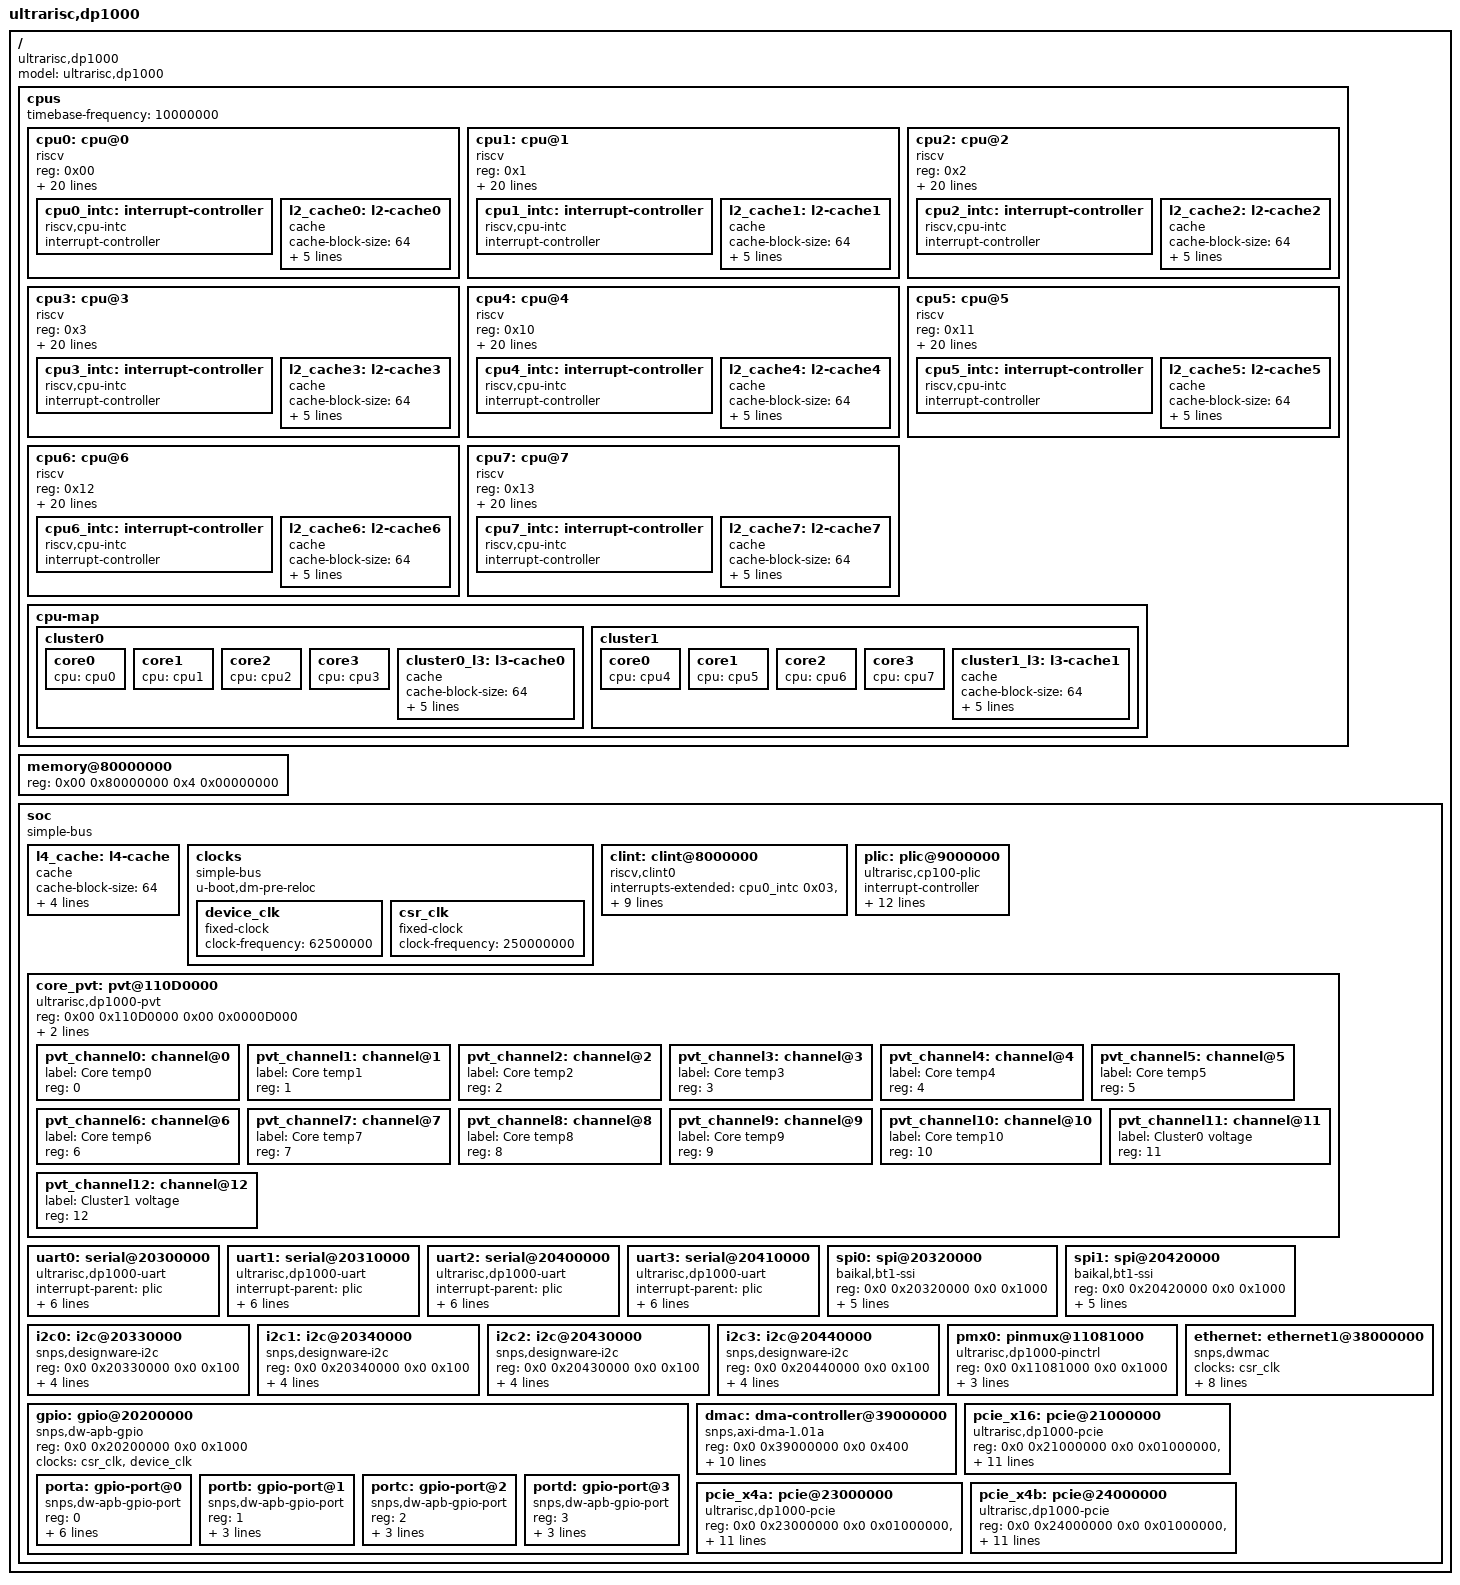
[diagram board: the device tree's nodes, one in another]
// SPDX-License-Identifier: GPL-2.0
/*
 * Copyright(C) 2025 UltraRISC Technology (Shanghai) Co., Ltd.
 */

/dts-v1/;

/ {
	#address-cells = <0x02>;
	#size-cells = <0x02>;
	compatible = "ultrarisc,dp1000";
	model = "ultrarisc,dp1000";

	cpus {
		#address-cells = <0x01>;
		#size-cells = <0x00>;
		timebase-frequency = <10000000>;

		cpu0: cpu@0 {
			device_type = "cpu";
			reg = <0x00>;
			status = "okay";
			compatible = "riscv";
			riscv,isa = "rv64imafdcbh";
			riscv,isa-base = "rv64i";
			riscv,isa-extensions = "i","m","a","f","d","c","h","zba",
					       "zbb","zbc","zbs","zicntr","zicsr",
					       "zifencei","zihpm","ziccif","ziccrse",
					       "ziccamoa","za64rs","zic64b","zicbom",
					       "zicbop","zicboz","zkt","zama16b",
					       "svade","ssccptr","sstvecd","sscounterenw",
					       "shcounterenw","shtvala","shvstvecd",
					       "shvsatpa","ssstrict","svvptc";
			mmu-type = "riscv,sv48";
			clock-frequency = <2000000000>;
			/* L1 I-cache and D-cache:
			 * block-size 64B
			 * 4-way set associative, size 64KB
			 * per-core.
			 */
			d-cache-block-size = <64>;
			d-cache-sets = <256>;
			d-cache-size = <0x10000>;
			i-cache-block-size = <64>;
			i-cache-sets = <256>;
			i-cache-size = <0x10000>;
			next-level-cache = <&l2_cache0>;
			riscv,cbom-block-size = <64>;
			riscv,cboz-block-size = <64>;
			cpu0_intc:interrupt-controller {
				#address-cells = <0x01>;
				interrupt-controller;
				compatible = "riscv,cpu-intc";
				#interrupt-cells = <0x01>;
			};
			l2_cache0: l2-cache0 {
				/* L2 cache:
				 * cache-unified, block-size 64B
				 * 8-way set associative, size 512KB
				 * per-core.
				 */
				compatible = "cache";
				cache-block-size = <64>;
				cache-level = <2>;
				cache-size = <0x80000>;
				cache-sets = <1024>;
				cache-unified;
				next-level-cache = <&cluster0_l3>;
			};
		};
		cpu1: cpu@1 {
			device_type = "cpu";
			reg = <0x1>;
			status = "okay";
			compatible = "riscv";
			riscv,isa = "rv64imafdcbh";
			riscv,isa-base = "rv64i";
			riscv,isa-extensions = "i","m","a","f","d","c","h","zba",
					       "zbb","zbc","zbs","zicntr","zicsr",
					       "zifencei","zihpm","ziccif","ziccrse",
					       "ziccamoa","za64rs","zic64b","zicbom",
					       "zicbop","zicboz","zkt","zama16b",
					       "svade","ssccptr","sstvecd","sscounterenw",
					       "shcounterenw","shtvala","shvstvecd",
					       "shvsatpa","ssstrict","svvptc";
			mmu-type = "riscv,sv48";
			clock-frequency = <2000000000>;
			/* L1 I-cache and D-cache:
			 * block-size 64B
			 * 4-way set associative, size 64KB
			 * per-core.
			 */
			d-cache-block-size = <64>;
			d-cache-sets = <256>;
			d-cache-size = <0x10000>;
			i-cache-block-size = <64>;
			i-cache-sets = <256>;
			i-cache-size = <0x10000>;
			next-level-cache = <&l2_cache1>;
			riscv,cbom-block-size = <64>;
			riscv,cboz-block-size = <64>;
			cpu1_intc:interrupt-controller {
				#address-cells = <0x01>;
				interrupt-controller;
				compatible = "riscv,cpu-intc";
				#interrupt-cells = <0x01>;
			};
			l2_cache1: l2-cache1 {
				/* L2 cache:
				 * cache-unified, block-size 64B
				 * 8-way set associative, size 512KB
				 * per-core.
				 */
				compatible = "cache";
				cache-block-size = <64>;
				cache-level = <2>;
				cache-size = <0x80000>;
				cache-sets = <1024>;
				cache-unified;
				next-level-cache = <&cluster0_l3>;
			};
		};
		cpu2: cpu@2 {
			device_type = "cpu";
			reg = <0x2>;
			status = "okay";
			compatible = "riscv";
			riscv,isa = "rv64imafdcbh";
			riscv,isa-base = "rv64i";
			riscv,isa-extensions = "i","m","a","f","d","c","h","zba",
					       "zbb","zbc","zbs","zicntr","zicsr",
					       "zifencei","zihpm","ziccif","ziccrse",
					       "ziccamoa","za64rs","zic64b","zicbom",
					       "zicbop","zicboz","zkt","zama16b",
					       "svade","ssccptr","sstvecd","sscounterenw",
					       "shcounterenw","shtvala","shvstvecd",
					       "shvsatpa","ssstrict","svvptc";
			mmu-type = "riscv,sv48";
			clock-frequency = <2000000000>;
			/* L1 I-cache and D-cache:
			 * block-size 64B
			 * 4-way set associative, size 64KB
			 * per-core.
			 */
			d-cache-block-size = <64>;
			d-cache-sets = <256>;
			d-cache-size = <0x10000>;
			i-cache-block-size = <64>;
			i-cache-sets = <256>;
			i-cache-size = <0x10000>;
			next-level-cache = <&l2_cache2>;
			riscv,cbom-block-size = <64>;
			riscv,cboz-block-size = <64>;
			cpu2_intc:interrupt-controller {
				#address-cells = <0x01>;
				interrupt-controller;
				compatible = "riscv,cpu-intc";
				#interrupt-cells = <0x01>;
			};
			l2_cache2: l2-cache2 {
				/* L2 cache:
				 * cache-unified, block-size 64B
				 * 8-way set associative, size 512KB
				 * per-core.
				 */
				compatible = "cache";
				cache-block-size = <64>;
				cache-level = <2>;
				cache-size = <0x80000>;
				cache-sets = <1024>;
				cache-unified;
				next-level-cache = <&cluster0_l3>;
			};
		};
		cpu3: cpu@3 {
			device_type = "cpu";
			reg = <0x3>;
			status = "okay";
			compatible = "riscv";
			riscv,isa = "rv64imafdcbh";
			riscv,isa-base = "rv64i";
			riscv,isa-extensions = "i","m","a","f","d","c","h","zba",
					       "zbb","zbc","zbs","zicntr","zicsr",
					       "zifencei","zihpm","ziccif","ziccrse",
					       "ziccamoa","za64rs","zic64b","zicbom",
					       "zicbop","zicboz","zkt","zama16b",
					       "svade","ssccptr","sstvecd","sscounterenw",
					       "shcounterenw","shtvala","shvstvecd",
					       "shvsatpa","ssstrict","svvptc";
			mmu-type = "riscv,sv48";
			clock-frequency = <2000000000>;
			/* L1 I-cache and D-cache:
			 * block-size 64B
			 * 4-way set associative, size 64KB
			 * per-core.
			 */
			d-cache-block-size = <64>;
			d-cache-sets = <256>;
			d-cache-size = <0x10000>;
			i-cache-block-size = <64>;
			i-cache-sets = <256>;
			i-cache-size = <0x10000>;
			next-level-cache = <&l2_cache3>;
			riscv,cbom-block-size = <64>;
			riscv,cboz-block-size = <64>;
			cpu3_intc:interrupt-controller {
				#address-cells = <0x01>;
				interrupt-controller;
				compatible = "riscv,cpu-intc";
				#interrupt-cells = <0x01>;
			};
			l2_cache3: l2-cache3 {
				/* L2 cache:
				 * cache-unified, block-size 64B
				 * 8-way set associative, size 512KB
				 * per-core.
				 */
				compatible = "cache";
				cache-block-size = <64>;
				cache-level = <2>;
				cache-size = <0x80000>;
				cache-sets = <1024>;
				cache-unified;
				next-level-cache = <&cluster0_l3>;
			};
		};
		cpu4: cpu@4 {
			device_type = "cpu";
			reg = <0x10>;
			status = "okay";
			compatible = "riscv";
			riscv,isa = "rv64imafdcbh";
			riscv,isa-base = "rv64i";
			riscv,isa-extensions = "i","m","a","f","d","c","h","zba",
					       "zbb","zbc","zbs","zicntr","zicsr",
					       "zifencei","zihpm","ziccif","ziccrse",
					       "ziccamoa","za64rs","zic64b","zicbom",
					       "zicbop","zicboz","zkt","zama16b",
					       "svade","ssccptr","sstvecd","sscounterenw",
					       "shcounterenw","shtvala","shvstvecd",
					       "shvsatpa","ssstrict","svvptc";
			mmu-type = "riscv,sv48";
			clock-frequency = <2000000000>;
			/* L1 I-cache and D-cache:
			 * block-size 64B
			 * 4-way set associative, size 64KB
			 * per-core.
			 */
			d-cache-block-size = <64>;
			d-cache-sets = <256>;
			d-cache-size = <0x10000>;
			i-cache-block-size = <64>;
			i-cache-sets = <256>;
			i-cache-size = <0x10000>;
			next-level-cache = <&l2_cache4>;
			riscv,cbom-block-size = <64>;
			riscv,cboz-block-size = <64>;
			cpu4_intc:interrupt-controller {
				#address-cells = <0x01>;
				interrupt-controller;
				compatible = "riscv,cpu-intc";
				#interrupt-cells = <0x01>;
			};
			l2_cache4: l2-cache4 {
				/* L2 cache:
				 * cache-unified, block-size 64B
				 * 8-way set associative, size 512KB
				 * per-core.
				 */
				compatible = "cache";
				cache-block-size = <64>;
				cache-level = <2>;
				cache-size = <0x80000>;
				cache-sets = <1024>;
				cache-unified;
				next-level-cache = <&cluster1_l3>;
			};
		};
		cpu5: cpu@5 {
			device_type = "cpu";
			reg = <0x11>;
			status = "okay";
			compatible = "riscv";
			riscv,isa = "rv64imafdcbh";
			riscv,isa-base = "rv64i";
			riscv,isa-extensions = "i","m","a","f","d","c","h","zba",
					       "zbb","zbc","zbs","zicntr","zicsr",
					       "zifencei","zihpm","ziccif","ziccrse",
					       "ziccamoa","za64rs","zic64b","zicbom",
					       "zicbop","zicboz","zkt","zama16b",
					       "svade","ssccptr","sstvecd","sscounterenw",
					       "shcounterenw","shtvala","shvstvecd",
					       "shvsatpa","ssstrict","svvptc";
			mmu-type = "riscv,sv48";
			clock-frequency = <2000000000>;
			/* L1 I-cache and D-cache:
			 * block-size 64B
			 * 4-way set associative, size 64KB
			 * per-core.
			 */
			d-cache-block-size = <64>;
			d-cache-sets = <256>;
			d-cache-size = <0x10000>;
			i-cache-block-size = <64>;
			i-cache-sets = <256>;
			i-cache-size = <0x10000>;
			next-level-cache = <&l2_cache5>;
			riscv,cbom-block-size = <64>;
			riscv,cboz-block-size = <64>;
			cpu5_intc:interrupt-controller {
				#address-cells = <0x01>;
				interrupt-controller;
				compatible = "riscv,cpu-intc";
				#interrupt-cells = <0x01>;
			};
			l2_cache5: l2-cache5 {
				/* L2 cache:
				 * cache-unified, block-size 64B
				 * 8-way set associative, size 512KB
				 * per-core.
				 */
				compatible = "cache";
				cache-block-size = <64>;
				cache-level = <2>;
				cache-size = <0x80000>;
				cache-sets = <1024>;
				cache-unified;
				next-level-cache = <&cluster1_l3>;
			};
		};
		cpu6: cpu@6 {
			device_type = "cpu";
			reg = <0x12>;
			status = "okay";
			compatible = "riscv";
			riscv,isa = "rv64imafdcbh";
			riscv,isa-base = "rv64i";
			riscv,isa-extensions = "i","m","a","f","d","c","h","zba",
					       "zbb","zbc","zbs","zicntr","zicsr",
					       "zifencei","zihpm","ziccif","ziccrse",
					       "ziccamoa","za64rs","zic64b","zicbom",
					       "zicbop","zicboz","zkt","zama16b",
					       "svade","ssccptr","sstvecd","sscounterenw",
					       "shcounterenw","shtvala","shvstvecd",
					       "shvsatpa","ssstrict","svvptc";
			mmu-type = "riscv,sv48";
			clock-frequency = <2000000000>;
			/* L1 I-cache and D-cache:
			 * block-size 64B
			 * 4-way set associative, size 64KB
			 * per-core.
			 */
			d-cache-block-size = <64>;
			d-cache-sets = <256>;
			d-cache-size = <0x10000>;
			i-cache-block-size = <64>;
			i-cache-sets = <256>;
			i-cache-size = <0x10000>;
			next-level-cache = <&l2_cache6>;
			riscv,cbom-block-size = <64>;
			riscv,cboz-block-size = <64>;
			cpu6_intc:interrupt-controller {
				#address-cells = <0x01>;
				interrupt-controller;
				compatible = "riscv,cpu-intc";
				#interrupt-cells = <0x01>;
			};
			l2_cache6: l2-cache6 {
				/* L2 cache:
				 * cache-unified, block-size 64B
				 * 8-way set associative, size 512KB
				 * per-core.
				 */
				compatible = "cache";
				cache-block-size = <64>;
				cache-level = <2>;
				cache-size = <0x80000>;
				cache-sets = <1024>;
				cache-unified;
				next-level-cache = <&cluster1_l3>;
			};
		};
		cpu7: cpu@7 {
			device_type = "cpu";
			reg = <0x13>;
			status = "okay";
			compatible = "riscv";
			riscv,isa = "rv64imafdcbh";
			riscv,isa-base = "rv64i";
			riscv,isa-extensions = "i","m","a","f","d","c","h","zba",
					       "zbb","zbc","zbs","zicntr","zicsr",
					       "zifencei","zihpm","ziccif","ziccrse",
					       "ziccamoa","za64rs","zic64b","zicbom",
					       "zicbop","zicboz","zkt","zama16b",
					       "svade","ssccptr","sstvecd","sscounterenw",
					       "shcounterenw","shtvala","shvstvecd",
					       "shvsatpa","ssstrict","svvptc";
			mmu-type = "riscv,sv48";
			clock-frequency = <2000000000>;
			/* L1 I-cache and D-cache:
			 * block-size 64B
			 * 4-way set associative, size 64KB
			 * per-core.
			 */
			d-cache-block-size = <64>;
			d-cache-sets = <256>;
			d-cache-size = <0x10000>;
			i-cache-block-size = <64>;
			i-cache-sets = <256>;
			i-cache-size = <0x10000>;
			next-level-cache = <&l2_cache7>;
			riscv,cbom-block-size = <64>;
			riscv,cboz-block-size = <64>;
			cpu7_intc:interrupt-controller {
				#address-cells = <0x01>;
				interrupt-controller;
				compatible = "riscv,cpu-intc";
				#interrupt-cells = <0x01>;
			};
			l2_cache7: l2-cache7 {
				/* L2 cache:
				 * cache-unified, block-size 64B
				 * 8-way set associative, size 512KB
				 * per-core.
				 */
				compatible = "cache";
				cache-block-size = <64>;
				cache-level = <2>;
				cache-size = <0x80000>;
				cache-sets = <1024>;
				cache-unified;
				next-level-cache = <&cluster1_l3>;
			};
		};

		cpu-map {
			cluster0: cluster0 {
				core0 {
					cpu = <&cpu0>;
				};
				core1 {
					cpu = <&cpu1>;
				};
				core2 {
					cpu = <&cpu2>;
				};
				core3 {
					cpu = <&cpu3>;
				};

				cluster0_l3: l3-cache0 {
					/* L3 cache:
					 * cache-unified, block-size 64B
					 * 16-way set associative, size 4MB
					 * per-cluster.
					 */
					compatible = "cache";
					cache-block-size = <64>;
					cache-level = <3>;
					cache-size = <0x400000>;
					cache-sets = <0x1000>;
					cache-unified;
					next-level-cache = <&l4_cache>;
				};
			};
			cluster1: cluster1 {
				core0 {
					cpu = <&cpu4>;
				};
				core1 {
					cpu = <&cpu5>;
				};
				core2 {
					cpu = <&cpu6>;
				};
				core3 {
					cpu = <&cpu7>;
				};
				cluster1_l3: l3-cache1 {
					/* L3 cache:
					 * cache-unified, block-size 64B
					 * 16-way set associative, size 4MB
					 * per-cluster.
					 */
					compatible = "cache";
					cache-block-size = <64>;
					cache-level = <3>;
					cache-size = <0x400000>;
					cache-sets = <0x1000>;
					cache-unified;
					next-level-cache = <&l4_cache>;
				};
			};
		};
	};

	memory@80000000 {
		device_type = "memory";
		reg = <0x00 0x80000000 0x4 0x00000000>;
	};

	soc {
		#address-cells = <0x02>;
		#size-cells = <0x02>;
		compatible = "simple-bus";
		ranges;

		l4_cache: l4-cache {
			/* L4 cache:
			 * cache-unified, block-size 64B
			 * 16-way set associative, size 16MB
			 * shared by the SoC.
			 */
			compatible = "cache";
			cache-block-size = <64>;
			cache-level = <4>;
			cache-size = <0x1000000>;
			cache-sets = <0x4000>;
			cache-unified;
		};

		clocks {
			compatible = "simple-bus";
			u-boot,dm-pre-reloc;
			device_clk: device_clk {
				compatible = "fixed-clock";
				clock-frequency = <62500000>;
				#clock-cells = <0>;
			};

			csr_clk: csr_clk {
				compatible = "fixed-clock";
				clock-frequency = <250000000>;
				#clock-cells = <0>;
			};
		};

		clint: clint@8000000 {
			compatible = "riscv,clint0";
			interrupts-extended = <&cpu0_intc 0x03>, <&cpu0_intc 0x07>,
					      <&cpu1_intc 0x03>, <&cpu1_intc 0x07>,
					      <&cpu2_intc 0x03>, <&cpu2_intc 0x07>,
					      <&cpu3_intc 0x03>, <&cpu3_intc 0x07>,
					      <&cpu4_intc 0x03>, <&cpu4_intc 0x07>,
					      <&cpu5_intc 0x03>, <&cpu5_intc 0x07>,
					      <&cpu6_intc 0x03>, <&cpu6_intc 0x07>,
					      <&cpu7_intc 0x03>, <&cpu7_intc 0x07>;
			reg = <0x00 0x8000000 0x00 0x100000>;
		};

		plic: plic@9000000 {
			#interrupt-cells = <1>;
			#address-cells = <0>;
			compatible = "ultrarisc,cp100-plic", "ultrarisc,dp1000-plic";
			interrupt-controller;
			interrupts-extended = <&cpu0_intc 0xb>, <&cpu0_intc 0x9>, <&cpu0_intc 0xa>,
					      <&cpu1_intc 0xb>, <&cpu1_intc 0x9>, <&cpu1_intc 0xa>,
					      <&cpu2_intc 0xb>, <&cpu2_intc 0x9>, <&cpu2_intc 0xa>,
					      <&cpu3_intc 0xb>, <&cpu3_intc 0x9>, <&cpu3_intc 0xa>,
					      <&cpu4_intc 0xb>, <&cpu4_intc 0x9>, <&cpu4_intc 0xa>,
					      <&cpu5_intc 0xb>, <&cpu5_intc 0x9>, <&cpu5_intc 0xa>,
					      <&cpu6_intc 0xb>, <&cpu6_intc 0x9>, <&cpu6_intc 0xa>,
					      <&cpu7_intc 0xb>, <&cpu7_intc 0x9>, <&cpu7_intc 0xa>;
			reg = <0x00 0x9000000 0x00 0x4000000>;
			riscv,max-priority = <0x07>;
			riscv,ndev = <160>;
		};

		core_pvt: pvt@110D0000 {
			compatible = "ultrarisc,dp1000-pvt";
			#address-cells = <1>;
			#size-cells = <0>;
			reg = <0x00 0x110D0000 0x00 0x0000D000>;
			clock-frequency = <250000000>;
			channels = <13>;
			#thermal-sensor-cells = <1>;

			pvt_channel0: channel@0 {
				label = "Core temp0";
				reg = <0>;
			};

			pvt_channel1: channel@1 {
				label = "Core temp1";
				reg = <1>;
			};

			pvt_channel2: channel@2 {
				label = "Core temp2";
				reg = <2>;
			};

			pvt_channel3: channel@3 {
				label = "Core temp3";
				reg = <3>;
			};

			pvt_channel4: channel@4 {
				label = "Core temp4";
				reg = <4>;
			};

			pvt_channel5: channel@5 {
				label = "Core temp5";
				reg = <5>;
			};
			pvt_channel6: channel@6 {
				label = "Core temp6";
				reg = <6>;
			};
			pvt_channel7: channel@7 {
				label = "Core temp7";
				reg = <7>;
			};
			pvt_channel8: channel@8 {
				label = "Core temp8";
				reg = <8>;
			};

			pvt_channel9: channel@9 {
				label = "Core temp9";
				reg = <9>;
			};
			pvt_channel10: channel@10 {
				label = "Core temp10";
				reg = <10>;
			};
			pvt_channel11: channel@11 {
				label = "Cluster0 voltage";
				reg = <11>;
			};
			pvt_channel12: channel@12 {
				label = "Cluster1 voltage";
				reg = <12>;
			};
		};

		uart0: serial@20300000 {
			interrupt-parent = <&plic>;
			interrupts = <17>;
			clock-frequency = <62500000>;
			current-speed = <115200>;
			reg = <0x00 0x20300000 0x00 0x10000>;
			compatible = "ultrarisc,dp1000-uart","ns16550";
			reg-offset = <0x0>;
			reg-shift = <0x02>;
		};

		uart1: serial@20310000 {
			interrupt-parent = <&plic>;
			interrupts = <18>;
			clock-frequency = <62500000>;
			current-speed = <115200>;
			reg = <0x00 0x20310000 0x00 0x10000>;
			compatible = "ultrarisc,dp1000-uart","ns16550";
			reg-offset = <0x0>;
			reg-shift = <0x02>;
		};

		uart2: serial@20400000 {
			interrupt-parent = <&plic>;
			interrupts = <25>;
			clock-frequency = <62500000>;
			current-speed = <115200>;
			reg = <0x00 0x20400000 0x00 0x10000>;
			compatible = "ultrarisc,dp1000-uart","ns16550";
			reg-offset = <0x0>;
			reg-shift = <0x02>;
		};

		uart3: serial@20410000 {
			interrupt-parent = <&plic>;
			interrupts = <26>;
			clock-frequency = <62500000>;
			current-speed = <115200>;
			reg = <0x00 0x20410000 0x00 0x10000>;
			compatible = "ultrarisc,dp1000-uart","ns16550";
			reg-offset = <0x0>;
			reg-shift = <0x02>;
		};

		spi0: spi@20320000 {
			compatible = "baikal,bt1-ssi","snps,dw-apb-ssi";
			status = "okay";
			#address-cells = <0x01>;
			#size-cells = <0x00>;
			reg = <0x0 0x20320000 0x0 0x1000>;
			interrupt-parent = <&plic>;
			interrupts = <19>;
			clocks = <&device_clk>;
			clock-names = "device_clk";
			num-cs = <3>;
			spi-max-frequency = <62500000>;
		};

		spi1: spi@20420000 {
			compatible = "baikal,bt1-ssi","snps,dw-apb-ssi";
			status = "okay";
			#address-cells = <0x01>;
			#size-cells = <0x00>;
			reg = <0x0 0x20420000 0x0 0x1000>;
			interrupt-parent = <&plic>;
			interrupts = <27>;
			clocks = <&device_clk>;
			clock-names = "device_clk";
			num-cs = <3>;
			spi-max-frequency = <62500000>;
		};

		i2c0: i2c@20330000{
			compatible = "snps,designware-i2c";
			status = "okay";
			#address-cells = <1>;
			#size-cells = <0>;
			reg = <0x0 0x20330000 0x0 0x100>;
			clock-frequency = <400000>;
			clocks = <&device_clk>;
			interrupt-parent = <&plic>;
			interrupts = <20>;
		};

		i2c1: i2c@20340000{
			compatible = "snps,designware-i2c";
			status = "okay";
			#address-cells = <1>;
			#size-cells = <0>;
			reg = <0x0 0x20340000 0x0 0x100>;
			clock-frequency = <400000>;
			clocks = <&device_clk>;
			interrupt-parent = <&plic>;
			interrupts = <21>;
		};

		i2c2: i2c@20430000{
			compatible = "snps,designware-i2c";
			status = "okay";
			#address-cells = <1>;
			#size-cells = <0>;
			reg = <0x0 0x20430000 0x0 0x100>;
			clock-frequency = <400000>;
			clocks = <&device_clk>;
			interrupt-parent = <&plic>;
			interrupts = <28>;
		};

		i2c3: i2c@20440000{
			compatible = "snps,designware-i2c";
			status = "okay";
			#address-cells = <1>;
			#size-cells = <0>;
			reg = <0x0 0x20440000 0x0 0x100>;
			clock-frequency = <400000>;
			clocks = <&device_clk>;
			interrupt-parent = <&plic>;
			interrupts = <29>;
		};

		pmx0: pinmux@11081000 {
			compatible = "ultrarisc,dp1000-pinctrl";
			reg = <0x0 0x11081000  0x0 0x1000>;
			#address-cells = <1>;
			#size-cells = <0>;
			#pinctrl-cells = <2>;
			pinctrl-single,register-width = <32>;
			pinctrl-single,function-mask = <0x3ff>;
			pinctrl-use-default;
		};

		gpio: gpio@20200000 {
			compatible = "snps,dw-apb-gpio";
      			#address-cells = <1>;
      			#size-cells = <0>;
			reg = <0x0 0x20200000 0x0 0x1000>;
      			clocks = <&csr_clk>, <&device_clk>;
			clock-names = "bus", "db";
			status = "okay";

			porta: gpio-port@0 {
				compatible = "snps,dw-apb-gpio-port";
				reg = <0>;
				gpio-controller;
				#gpio-cells = <2>;
				snps,nr-gpios = <16>;
				interrupt-controller;
				#interrupt-cells = <2>;
				interrupt-parent = <&plic>;
				interrupts = <34>;
				gpio-ranges = <&pmx0 0 0 16>;
			};

			portb: gpio-port@1 {
				compatible = "snps,dw-apb-gpio-port";
				reg = <1>;
				gpio-controller;
				#gpio-cells = <2>;
				snps,nr-gpios = <8>;
				gpio-ranges = <&pmx0 16 0 8>;
			};

			portc: gpio-port@2 {
				compatible = "snps,dw-apb-gpio-port";
				reg = <2>;
				gpio-controller;
				#gpio-cells = <2>;
				snps,nr-gpios = <8>;
				gpio-ranges = <&pmx0 24 0 8>;
			};

			portd: gpio-port@3 {
				compatible = "snps,dw-apb-gpio-port";
				reg = <3>;
				gpio-controller;
				#gpio-cells = <2>;
				snps,nr-gpios = <8>;
				gpio-ranges = <&pmx0 32 0 8>;
			};
		};

		ethernet: ethernet1@38000000 {
			clocks = <&csr_clk>;
			clock-names = "stmmaceth";
			compatible = "snps,dwmac", "snps,dwmac-5.10a";
			interrupt-parent = <&plic>;
			interrupts = <84>;
			interrupt-names = "macirq";
			reg = <0x00 0x38000000 0x00 0x1000000>;
			local-mac-address = [ff ff ff ff ff ff];
			phy-mode = "rgmii";
			max-speed = <1000>;
			snps,txpbl = <8>;
			snps,rxpbl = <8>;
		};

		dmac: dma-controller@39000000 {
			compatible = "snps,axi-dma-1.01a";
			#address-cells = <1>;
			#size-cells = <0>;
			reg = <0x0 0x39000000 0x0 0x400>;
			clocks = <&device_clk>, <&device_clk>;
			clock-names = "core-clk", "cfgr-clk";
			interrupt-parent = <&plic>;
			interrupts = <152>;
			#dma-cells = <1>;
			dma-channels = <8>;
			snps,dma-masters = <1>;
			snps,data-width = <4>;
			snps,block-size = <512 512 512 512 512 512 512 512>;
			snps,priority = <0 1 2 3 4 5 6 7>;
			snps,axi-max-burst-len = <256>;
		};

		pcie_x16: pcie@21000000 {
			compatible = "ultrarisc,dp1000-pcie", "ultrarisc,dw-pcie";
			#address-cells = <3>;
			#size-cells = <2>;
			#interrupt-cells = <1>;
			reg = <0x0 0x21000000 0x0 0x01000000>, /* IP registers */
			      <0x0 0x4fff0000 0x0 0x00010000>; /* Configuration space */
			reg-names = "dbi", "config";
			device_type = "pci";
			dma-coherent;
			bus-range = <0x0 0xff>;
			num-lanes = <16>;
			/* ranges:
			 *   io
			 *   mem32
			 *   mem64 prefetchable
			 */
			ranges = <0x81000000  0x0 0x4fbf0000  0x0 0x4fbf0000  0x0 0x00400000>,
				 <0x82000000  0x0 0x40000000  0x0 0x40000000  0x0 0x0fbf0000>,
				 <0xc3000000 0x40 0x00000000 0x40 0x00000000  0xd 0x00000000>;
			max-link-speed = <4>;
			interrupt-parent = <&plic>;
			interrupts = <43>, <44>, <45>, <46>, <47>;
			interrupt-names = "msi", "inta", "intb", "intc", "intd";
			interrupt-map-mask = <0x0 0x0 0x0 0x7>;
			interrupt-map = <0x0 0x0 0x0 0x1 &plic 44>,
					<0x0 0x0 0x0 0x2 &plic 45>,
					<0x0 0x0 0x0 0x3 &plic 46>,
					<0x0 0x0 0x0 0x4 &plic 47>;
		};

		pcie_x4a: pcie@23000000 {
			compatible = "ultrarisc,dp1000-pcie", "ultrarisc,dw-pcie";
			#address-cells = <3>;
			#size-cells = <2>;
			#interrupt-cells = <1>;
			reg = <0x0 0x23000000 0x0 0x01000000>, /* IP registers */
			      <0x0 0x6fff0000 0x0 0x00010000>; /* Configuration space */
			reg-names = "dbi", "config";
			device_type = "pci";
			dma-coherent;
			bus-range = <0x0 0xff>;
			num-lanes = <4>;
			/* ranges:
			 *   io
			 *   mem32
			 *   mem64 prefetchable
			 */
			ranges = <0x81000000  0x0 0x6fbf0000  0x0 0x6fbf0000  0x0 0x00400000>,
				 <0x82000000  0x0 0x60000000  0x0 0x60000000  0x0 0x0fbf0000>,
				 <0xc3000000 0x80 0x00000000 0x80 0x00000000  0xd 0x00000000>;
			max-link-speed = <4>;
			interrupt-parent = <&plic>;
			interrupts = <63>, <64>, <65>, <66>, <67>;
			interrupt-names = "msi", "inta", "intb", "intc", "intd";
			interrupt-map-mask = <0x0 0x0 0x0 0x7>;
			interrupt-map = <0x0 0x0 0x0 0x1 &plic 64>,
					<0x0 0x0 0x0 0x2 &plic 65>,
					<0x0 0x0 0x0 0x3 &plic 66>,
					<0x0 0x0 0x0 0x4 &plic 67>;
		};

		pcie_x4b: pcie@24000000 {
			compatible = "ultrarisc,dp1000-pcie", "ultrarisc,dw-pcie";
			#address-cells = <3>;
			#size-cells = <2>;
			#interrupt-cells = <1>;
			reg = <0x0 0x24000000 0x0 0x01000000>, /* IP registers */
			      <0x0 0x7fff0000 0x0 0x00010000>; /* Configuration space */
			reg-names = "dbi", "config";
			device_type = "pci";
			dma-coherent;
			bus-range = <0x0 0xff>;
			num-lanes = <4>;
			/* ranges:
			 *   io
			 *   mem32
			 *   mem64 prefetchable
			 */
			ranges = <0x81000000  0x0 0x7fbf0000  0x0 0x7fbf0000 0x0 0x00400000>,
				 <0x82000000  0x0 0x70000000  0x0 0x70000000 0x0 0x0fbf0000>,
				 <0xc3000000 0xc0 0x00000000 0xc0 0x00000000 0xd 0x00000000>;
			max-link-speed = <4>;
			interrupt-parent = <&plic>;
			interrupts = <73>, <74>, <75>, <76>, <77>;
			interrupt-names = "msi", "inta", "intb", "intc", "intd";
			interrupt-map-mask = <0x0 0x0 0x0 0x7>;
			interrupt-map = <0x0 0x0 0x0 0x1 &plic 74>,
					<0x0 0x0 0x0 0x2 &plic 75>,
					<0x0 0x0 0x0 0x3 &plic 76>,
					<0x0 0x0 0x0 0x4 &plic 77>;
		};
	};
};
